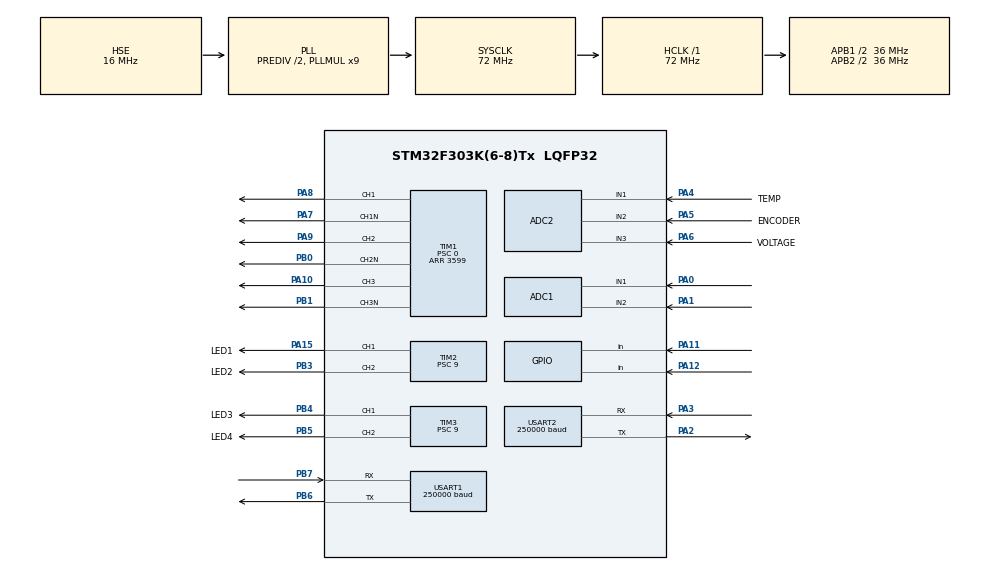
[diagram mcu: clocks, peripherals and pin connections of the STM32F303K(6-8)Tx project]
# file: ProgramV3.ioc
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ADC1.Channel-0\#ChannelRegularConversion=ADC_CHANNEL_1
ADC1.Channel-1\#ChannelRegularConversion=ADC_CHANNEL_2
ADC1.ContinuousConvMode=ENABLE
ADC1.DMAContinuousRequests=ENABLE
ADC1.NbrOfConversion=2
ADC1.NbrOfConversionFlag=1
ADC1.Offset-0\#ChannelRegularConversion=0
ADC1.Offset-1\#ChannelRegularConversion=0
ADC1.OffsetNumber-0\#ChannelRegularConversion=ADC_OFFSET_NONE
ADC1.OffsetNumber-1\#ChannelRegularConversion=ADC_OFFSET_NONE
ADC1.Rank-0\#ChannelRegularConversion=1
ADC1.Rank-1\#ChannelRegularConversion=2
ADC1.SamplingTime-0\#ChannelRegularConversion=ADC_SAMPLETIME_61CYCLES_5
ADC1.SamplingTime-1\#ChannelRegularConversion=ADC_SAMPLETIME_61CYCLES_5
ADC1.SamplingTimeOPAMP-1\#ChannelRegularConversion=ADC_SAMPLETIME_61CYCLES_5
ADC1.master=1
ADC2.Channel-0\#ChannelRegularConversion=ADC_CHANNEL_2
ADC2.Channel-1\#ChannelRegularConversion=ADC_CHANNEL_3
ADC2.Channel-4\#ChannelRegularConversion=ADC_CHANNEL_1
ADC2.ClockPrescaler=ADC_CLOCK_ASYNC_DIV1
ADC2.ContinuousConvMode=ENABLE
ADC2.DMAContinuousRequests=ENABLE
ADC2.EOCSelection=ADC_EOC_SINGLE_CONV
ADC2.EnableAnalogWatchDog1=false
ADC2.NbrOfConversion=3
ADC2.NbrOfConversionFlag=1
ADC2.Offset-0\#ChannelRegularConversion=0
ADC2.Offset-1\#ChannelRegularConversion=0
ADC2.Offset-4\#ChannelRegularConversion=0
ADC2.OffsetNumber-0\#ChannelRegularConversion=ADC_OFFSET_NONE
ADC2.OffsetNumber-1\#ChannelRegularConversion=ADC_OFFSET_NONE
ADC2.OffsetNumber-4\#ChannelRegularConversion=ADC_OFFSET_NONE
ADC2.Rank-0\#ChannelRegularConversion=1
ADC2.Rank-1\#ChannelRegularConversion=2
ADC2.Rank-4\#ChannelRegularConversion=3
ADC2.SamplingTime-0\#ChannelRegularConversion=ADC_SAMPLETIME_61CYCLES_5
ADC2.SamplingTime-1\#ChannelRegularConversion=ADC_SAMPLETIME_601CYCLES_5
ADC2.SamplingTime-4\#ChannelRegularConversion=ADC_SAMPLETIME_601CYCLES_5
ADC2.SamplingTimeOPAMP-1\#ChannelRegularConversion=ADC_SAMPLETIME_61CYCLES_5
ADC2.SamplingTimeOPAMP-4\#ChannelRegularConversion=ADC_SAMPLETIME_61CYCLES_5
ADC2.SubFamily=STM32F303x8
Dma.ADC1.5.Direction=DMA_PERIPH_TO_MEMORY
Dma.ADC1.5.Instance=DMA1_Channel1
Dma.ADC1.5.MemDataAlignment=DMA_MDATAALIGN_HALFWORD
Dma.ADC1.5.MemInc=DMA_MINC_ENABLE
Dma.ADC1.5.Mode=DMA_CIRCULAR
Dma.ADC1.5.PeriphDataAlignment=DMA_PDATAALIGN_HALFWORD
Dma.ADC1.5.PeriphInc=DMA_PINC_DISABLE
Dma.ADC1.5.Priority=DMA_PRIORITY_LOW
Dma.ADC2.0.Direction=DMA_PERIPH_TO_MEMORY
Dma.ADC2.0.Instance=DMA1_Channel2
Dma.ADC2.0.MemDataAlignment=DMA_MDATAALIGN_HALFWORD
Dma.ADC2.0.MemInc=DMA_MINC_ENABLE
Dma.ADC2.0.Mode=DMA_CIRCULAR
Dma.ADC2.0.PeriphDataAlignment=DMA_PDATAALIGN_HALFWORD
Dma.ADC2.0.PeriphInc=DMA_PINC_DISABLE
Dma.ADC2.0.Priority=DMA_PRIORITY_LOW
Dma.Request0=ADC2
Dma.Request1=USART1_TX
Dma.Request2=USART1_RX
Dma.Request3=USART2_RX
Dma.Request4=USART2_TX
Dma.Request5=ADC1
Dma.USART1_RX.2.Direction=DMA_PERIPH_TO_MEMORY
Dma.USART1_RX.2.Instance=DMA1_Channel5
Dma.USART1_RX.2.MemDataAlignment=DMA_MDATAALIGN_BYTE
Dma.USART1_RX.2.MemInc=DMA_MINC_ENABLE
Dma.USART1_RX.2.Mode=DMA_CIRCULAR
Dma.USART1_RX.2.PeriphDataAlignment=DMA_PDATAALIGN_BYTE
Dma.USART1_RX.2.PeriphInc=DMA_PINC_DISABLE
Dma.USART1_RX.2.Priority=DMA_PRIORITY_LOW
Dma.USART1_TX.1.Direction=DMA_MEMORY_TO_PERIPH
Dma.USART1_TX.1.Instance=DMA1_Channel4
Dma.USART1_TX.1.MemDataAlignment=DMA_MDATAALIGN_BYTE
Dma.USART1_TX.1.MemInc=DMA_MINC_ENABLE
Dma.USART1_TX.1.Mode=DMA_CIRCULAR
Dma.USART1_TX.1.PeriphDataAlignment=DMA_PDATAALIGN_BYTE
Dma.USART1_TX.1.PeriphInc=DMA_PINC_DISABLE
Dma.USART1_TX.1.Priority=DMA_PRIORITY_LOW
Dma.USART2_RX.3.Direction=DMA_PERIPH_TO_MEMORY
Dma.USART2_RX.3.Instance=DMA1_Channel6
Dma.USART2_RX.3.MemDataAlignment=DMA_MDATAALIGN_BYTE
Dma.USART2_RX.3.MemInc=DMA_MINC_ENABLE
Dma.USART2_RX.3.Mode=DMA_CIRCULAR
Dma.USART2_RX.3.PeriphDataAlignment=DMA_PDATAALIGN_BYTE
Dma.USART2_RX.3.PeriphInc=DMA_PINC_DISABLE
Dma.USART2_RX.3.Priority=DMA_PRIORITY_LOW
Dma.USART2_TX.4.Direction=DMA_MEMORY_TO_PERIPH
Dma.USART2_TX.4.Instance=DMA1_Channel7
Dma.USART2_TX.4.MemDataAlignment=DMA_MDATAALIGN_BYTE
Dma.USART2_TX.4.MemInc=DMA_MINC_ENABLE
Dma.USART2_TX.4.Mode=DMA_CIRCULAR
Dma.USART2_TX.4.PeriphDataAlignment=DMA_PDATAALIGN_BYTE
Dma.USART2_TX.4.PeriphInc=DMA_PINC_DISABLE
Dma.USART2_TX.4.Priority=DMA_PRIORITY_LOW
Mcu.Family=STM32F3
Mcu.Name=STM32F303K(6-8)Tx
Mcu.Package=LQFP32
NVIC.DMA1_Channel1_IRQn=true\:0\:0\:false\:false\:true\:false\:true\:true
NVIC.DMA1_Channel2_IRQn=true\:0\:0\:false\:false\:true\:false\:true\:true
NVIC.DMA1_Channel4_IRQn=true\:0\:0\:false\:false\:true\:false\:true\:true
NVIC.DMA1_Channel5_IRQn=true\:0\:0\:false\:false\:true\:false\:true\:true
NVIC.DMA1_Channel6_IRQn=true\:0\:0\:false\:false\:true\:false\:true\:true
NVIC.DMA1_Channel7_IRQn=true\:0\:0\:false\:false\:true\:false\:true\:true
NVIC.PriorityGroup=NVIC_PRIORITYGROUP_4
PA0.Mode=IN1-Single-Ended
PA0.Signal=ADC1_IN1
PA1.Mode=IN2-Single-Ended
PA1.Signal=ADC1_IN2
PA10.Signal=S_TIM1_CH3
PA11.Signal=GPIO_Input
PA12.Signal=GPIO_Input
PA13.Mode=Serial_Wire
PA13.Signal=SYS_JTMS-SWDIO
PA14.Mode=Serial_Wire
PA14.Signal=SYS_JTCK-SWCLK
PA15.GPIO_Label=LED1
PA15.Signal=S_TIM2_CH1_ETR
PA2.Mode=Asynchronous
PA2.Signal=USART2_TX
PA3.Mode=Asynchronous
PA3.Signal=USART2_RX
PA4.GPIO_Label=TEMP
PA4.Mode=IN1-Single-Ended
PA4.Signal=ADC2_IN1
PA5.GPIO_Label=ENCODER
PA5.Mode=IN2-Single-Ended
PA5.Signal=ADC2_IN2
PA6.GPIO_Label=VOLTAGE
PA6.Mode=IN3-Single-Ended
PA6.Signal=ADC2_IN3
PA7.Mode=PWM Generation1 CH1 CH1N
PA7.Signal=TIM1_CH1N
PA8.Signal=S_TIM1_CH1
PA9.Signal=S_TIM1_CH2
PB0.Mode=PWM Generation2 CH2 CH2N
PB0.Signal=TIM1_CH2N
PB1.Mode=PWM Generation3 CH3 CH3N
PB1.Signal=TIM1_CH3N
PB3.GPIO_Label=LED2
PB3.Signal=S_TIM2_CH2
PB4.GPIO_Label=LED3
PB4.Signal=S_TIM3_CH1
PB5.GPIO_Label=LED4
PB5.Signal=S_TIM3_CH2
PB6.Mode=Asynchronous
PB6.Signal=USART1_TX
PB7.Mode=Asynchronous
PB7.Signal=USART1_RX
PF0\ /\ OSC_IN.Mode=HSE-External-Oscillator
PF0\ /\ OSC_IN.Signal=RCC_OSC_IN
PF1\ /\ OSC_OUT.Mode=HSE-External-Oscillator
PF1\ /\ OSC_OUT.Signal=RCC_OSC_OUT
ProjectManager.HeapSize=0x200
ProjectManager.StackSize=0x400
ProjectManager.TargetToolchain=Makefile
RCC.AHBFreq_Value=72000000
RCC.APB1CLKDivider=RCC_HCLK_DIV2
RCC.APB1Freq_Value=36000000
RCC.APB1TimFreq_Value=72000000
RCC.APB2CLKDivider=RCC_HCLK_DIV2
RCC.APB2Freq_Value=36000000
RCC.APB2TimFreq_Value=72000000
RCC.CortexFreq_Value=72000000
RCC.HCLKFreq_Value=72000000
RCC.HSE_VALUE=16000000
RCC.HSI_VALUE=8000000
RCC.PLLMUL=RCC_PLL_MUL9
RCC.PLLSourceVirtual=RCC_PLLSOURCE_HSE
RCC.RCC_PLLsource_Clock_Source_FROM_HSE=RCC_HSE_PREDIV_DIV2
RCC.SYSCLKFreq_VALUE=72000000
RCC.SYSCLKSourceVirtual=RCC_SYSCLKSOURCE_PLLCLK
SH.S_TIM1_CH1.0=TIM1_CH1,PWM Generation1 CH1 CH1N
SH.S_TIM1_CH2.0=TIM1_CH2,PWM Generation2 CH2 CH2N
SH.S_TIM1_CH3.0=TIM1_CH3,PWM Generation3 CH3 CH3N
SH.S_TIM2_CH1_ETR.0=TIM2_CH1,PWM Generation1 CH1
SH.S_TIM2_CH2.0=TIM2_CH2,PWM Generation2 CH2
SH.S_TIM3_CH1.0=TIM3_CH1,PWM Generation1 CH1
SH.S_TIM3_CH2.0=TIM3_CH2,PWM Generation2 CH2
TIM1.BreakState=TIM_BREAK_DISABLE
TIM1.Channel-PWM\ Generation1\ CH1\ CH1N=TIM_CHANNEL_1
TIM1.Channel-PWM\ Generation2\ CH2\ CH2N=TIM_CHANNEL_2
TIM1.Channel-PWM\ Generation3\ CH3\ CH3N=TIM_CHANNEL_3
TIM1.DeadTime=20
TIM1.Period=3599
TIM1.Prescaler=0
TIM2.Channel-PWM\ Generation1\ CH1=TIM_CHANNEL_1
TIM2.Channel-PWM\ Generation2\ CH2=TIM_CHANNEL_2
TIM2.Period=5999
TIM2.Prescaler=9
TIM3.Channel-PWM\ Generation1\ CH1=TIM_CHANNEL_1
TIM3.Channel-PWM\ Generation2\ CH2=TIM_CHANNEL_2
TIM3.Period=3599
TIM3.Prescaler=9
USART1.BaudRate=250000
USART1.VirtualMode-Asynchronous=VM_ASYNC
USART2.BaudRate=250000
USART2.VirtualMode-Asynchronous=VM_ASYNC
board=custom

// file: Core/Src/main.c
/* USER CODE BEGIN Header */
/**
 ******************************************************************************
 * @file           : main.c
 * @brief          : Main program body
 ******************************************************************************
 * @attention
 *
 * Copyright (c) 2025 STMicroelectronics.
 * All rights reserved.
 *
 * This software is licensed under terms that can be found in the LICENSE file
 * in the root directory of this software component.
 * If no LICENSE file comes with this software, it is provided AS-IS.
 *
 ******************************************************************************
 */
/* USER CODE END Header */
#include "main.h"
#include "adc.h"
#include "dma.h"
#include "tim.h"
#include "usart.h"
#include "gpio.h"

/* USER CODE BEGIN Includes */
#include "app.h"
#include "stdio.h"
/* USER CODE END Includes */

void SystemClock_Config(void);

/* USER CODE BEGIN 0 */
int _write(int file, char* ptr, int len) {
  HAL_UART_Transmit(&huart1, (uint8_t*)ptr, len, 10);
  return len;
}

/* USER CODE END 0 */

int main(void)
{

  /* USER CODE BEGIN 1 */
  setbuf(stdout, NULL);
  /* USER CODE END 1 */

  /* MCU Configuration--------------------------------------------------------*/

  /* Reset of all peripherals, Initializes the Flash interface and the Systick. */
  HAL_Init();

  /* Configure the system clock */
  SystemClock_Config();

  /* Initialize all configured peripherals */
  MX_GPIO_Init();
  MX_DMA_Init();
  MX_TIM1_Init();
  MX_USART1_UART_Init();
  MX_USART2_UART_Init();
  MX_ADC2_Init();
  MX_TIM2_Init();
  MX_TIM3_Init();
  MX_ADC1_Init();

  /* Infinite loop */
  /* USER CODE BEGIN WHILE */
  Setup();

  ForcedCommutationCurrentTest();  // 強制転流しながら電流計測
  // CurrentSenseTest();  // 停止状態での電流計測
  // MainApp();
  while (1) {
    /* USER CODE END WHILE */

  }
}

void SystemClock_Config(void)
{
  RCC_OscInitTypeDef RCC_OscInitStruct = {0};
  RCC_ClkInitTypeDef RCC_ClkInitStruct = {0};
  RCC_PeriphCLKInitTypeDef PeriphClkInit = {0};

  /** Initializes the RCC Oscillators according to the specified parameters
  * in the RCC_OscInitTypeDef structure.
  */
  RCC_OscInitStruct.OscillatorType = RCC_OSCILLATORTYPE_HSE;
  RCC_OscInitStruct.HSEState = RCC_HSE_ON;
  RCC_OscInitStruct.HSEPredivValue = RCC_HSE_PREDIV_DIV2;
  RCC_OscInitStruct.HSIState = RCC_HSI_ON;
  RCC_OscInitStruct.PLL.PLLState = RCC_PLL_ON;
  RCC_OscInitStruct.PLL.PLLSource = RCC_PLLSOURCE_HSE;
  RCC_OscInitStruct.PLL.PLLMUL = RCC_PLL_MUL9;
  if (HAL_RCC_OscConfig(&RCC_OscInitStruct) != HAL_OK)
  {
    Error_Handler();
  }

  /** Initializes the CPU, AHB and APB buses clocks
  */
  RCC_ClkInitStruct.ClockType = RCC_CLOCKTYPE_HCLK|RCC_CLOCKTYPE_SYSCLK
                              |RCC_CLOCKTYPE_PCLK1|RCC_CLOCKTYPE_PCLK2;
  RCC_ClkInitStruct.SYSCLKSource = RCC_SYSCLKSOURCE_PLLCLK;
  RCC_ClkInitStruct.AHBCLKDivider = RCC_SYSCLK_DIV1;
  RCC_ClkInitStruct.APB1CLKDivider = RCC_HCLK_DIV2;
  RCC_ClkInitStruct.APB2CLKDivider = RCC_HCLK_DIV2;

  if (HAL_RCC_ClockConfig(&RCC_ClkInitStruct, FLASH_LATENCY_2) != HAL_OK)
  {
    Error_Handler();
  }
  PeriphClkInit.PeriphClockSelection = RCC_PERIPHCLK_USART1|RCC_PERIPHCLK_TIM1
                              |RCC_PERIPHCLK_ADC12;
  PeriphClkInit.Usart1ClockSelection = RCC_USART1CLKSOURCE_PCLK1;
  PeriphClkInit.Adc12ClockSelection = RCC_ADC12PLLCLK_DIV1;
  PeriphClkInit.Tim1ClockSelection = RCC_TIM1CLK_HCLK;
  if (HAL_RCCEx_PeriphCLKConfig(&PeriphClkInit) != HAL_OK)
  {
    Error_Handler();
  }
}

void Error_Handler(void)
{
  __disable_irq();
  while (1) {
  }
}
